# uartSpirit: IP-XACT component
VLNV spiritconsortium.org:Leon2RTL:uartSpirit:1.2

## Parameters
EXTBAUD = false

## Bus interfaces (logical=physical port)
APBClk: slave spiritconsortium.org:busdef.clock:clock:1.0
  CLK=clk
APBReset: slave spiritconsortium.org:busdef.reset:reset:1.0
  RESETn=rst
ambaAPB: slave amba.com:AMBA2:APB:r2p0_4, memory map ambaAPB
  Select=psel, Enable=penable, Address=paddr, Write=pwrite, WriteData=pwdata, ReadData=prdata, Clock=clk, Resetn=rst
Interrupt: master spiritconsortium.org:busdef.interrupt:interrupt:1.0
  IRQ=irq
serial: master spiritconsortium.org:busdef.generic:serial:1.0
  RxD=rxd, TxD=txd, CTSn=ctsn, RTSn=rtsn, DTRn=rxen

## Ports
in clk
in rst
in psel
in penable
in paddr[31:0]
in pwrite
in pwdata[31:0]
out prdata[31:0]
out irq
in scaler[7:0]
in rxd
out rxen
out txd
out txen
out flow
out rtsn
in ctsn

## Address spaces and blocks
ambaAPB.defaultid4489950: base 0, range 16, width 32

## Registers
Registers are 32-bit, read-write, no defined reset value unless marked. A register's access mark holds for its fields unless they carry their own. Offsets are from the block's base; lines under a group give offsets from that group; [hi:lo] are bit positions; {n}, {i} and the like mark numbered series; 'fields as' and 'values as' point back to an identical list; <NAME> marks a mode.

## ambaAPB.defaultid4489950
Base 0x00000000
0x00 data — Data read/write register
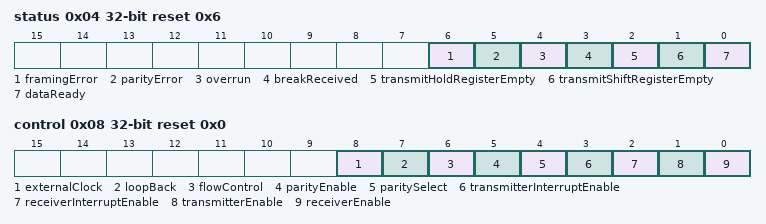
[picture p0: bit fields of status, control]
0x04 status reset 0x6
  [6] framingError — Indicates thata framing error was detected
  [5] parityError — Indicates that a parity error was detected
  [4] overrun — Indicates that one or more characters was lost due to an overrun
  [3] breakReceived — Indicates that the a BREAK has been received
  [2] transmitHoldRegisterEmpty ro — Indicates that the transmitter hold register is empty
  [1] transmitShiftRegisterEmpty ro — Indicates that the transmitter shift register is empty
  [0] dataReady ro — Indicates that new data is available in the receiver holding register
0x08 control reset 0x0 (reset mask 0x143)
  [8] externalClock — If set, the UART scaler will be clocked from EXTCLK
  [7] loopBack — If set, loopback mode will be enabled
  [6] flowControl — If set, enables flow control using CTS/RTS
  [5] parityEnable — If set, enables parity generation and checking
  [4] paritySelect — Selects parity polarity (0=odd parity, 1=even parity)
    0=oddParity; 1=evenParity
  [3] transmitterInterruptEnable — If set, enables generation of transmit interrupt
  [2] receiverInterruptEnable — If set, enables generation of receive interrupt
  [1] transmitterEnable — If set, enables transmitter
  [0] receiverEnable — If set, enables receiver
0x0C scalarReload
  [11:0] scalarReloadValue

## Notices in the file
Copyright (c) 2006, 2008, 2009 The SPIRIT Consortium.
This work forms part of a deliverable of The SPIRIT Consortium.
Use of these materials are governed by the legal terms and conditions
outlined in the disclaimer available from www.spiritconsortium.org.
This source file is provided on an AS IS basis.  The SPIRIT
Consortium disclaims any warranty express or implied including
any warranty of merchantability and fitness for use for a
particular purpose.
The user of the source file shall indemnify and hold The SPIRIT
Consortium and its members harmless from any damages or liability.
